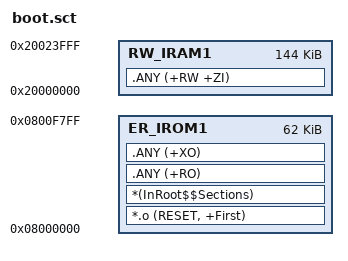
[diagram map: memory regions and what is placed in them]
; Boot链接脚本。
; Boot代码区：0x08000000~0x0800F800，共62K。

LR_IROM1 0x08000000 0x0000F800  {
  ER_IROM1 0x08000000 0x0000F800  {
   *.o (RESET, +First)
   *(InRoot$$Sections)
   .ANY (+RO)
   .ANY (+XO)
  }
  RW_IRAM1 0x20000000 0x00024000  {
   .ANY (+RW +ZI)
  }
}
